# A31S13x register map
Vendor: VENDOR ABOV Semiconductor Co., Ltd.; Series: A31S13x; File version: 1.0
CPU: CM0+ r0p1, little endian, no MPU, no FPU, VTOR, 2 interrupt priority bits
Registers are 32-bit, read-write, reset 0x0 unless marked. A register's access mark holds for its fields unless they carry their own. Offsets are from the block's base; [hi:lo] are bit positions; 'fields as' and 'values as' point back to an identical list.

## TIMER2n — Timer/Counter 2n
Base 0x52000000
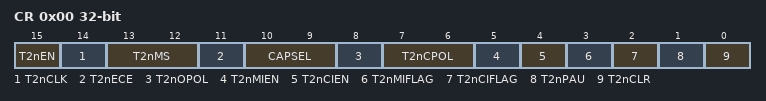
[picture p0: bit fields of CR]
0x00 CR — TIMER2n Control Register
  [15] T2nEN — TIMER2n Operation Enable
  [14] T2nCLK — TIMER2n Clock Selection
  [13:12] T2nMS — TIMER2n Operation Mode Selection
  [11] T2nECE — TIMER2n External Clock Edge Selection
  [10:9] CAPSEL — TIMER2n Capture Signal Selection
  [8] T2nOPOL — TIMER2n Output Polarity Selection
  [7:6] T2nCPOL — TIMER2n Capture Polarity Selection
  [5] T2nMIEN — TIMER2n Match Interrupt Enable
  [4] T2nCIEN — TIMER2n Capture Interrupt Enable
  [3] T2nMIFLAG — TIMER2n Match Interrupt Flag
  [2] T2nCIFLAG — TIMER2n Capture Interrupt Flag
  [1] T2nPAU — TIMER2n Counter Temporary Pause Control
  [0] T2nCLR — TIMER2n Counter and Prescaler Clear
0x04 ADR reset 0xFFFFFFFF — TIMER2n A Data Register
  [31:0] ADATA — TIMER2n A Data
0x08 BDR reset 0xFFFFFFFF — TIMER2n B Data Register
  [31:0] BDATA — TIMER2n B Data
0x0C CAPDR ro — TIMER2n Capture Data Register
  [31:0] CAPD — TIMER2n Capture Data
0x10 PREDR reset 0xFFF — TIMER2n Prescaler Data Register
  [11:0] PRED — TIMER2n Prescaler Data
0x14 CNT ro — TIMER2n Counter Register
  [31:0] CNT — TIMER2n Counter

## TIMER20 — Timer/Counter 20
Base 0x40002500
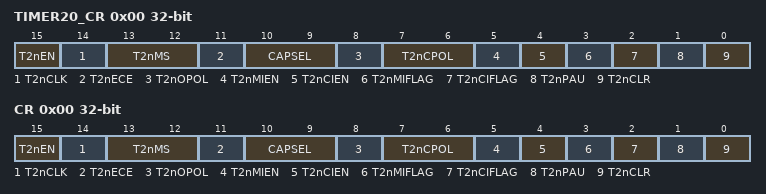
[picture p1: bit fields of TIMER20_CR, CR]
0x00 TIMER20_CR (alternate view of CR) — TIMER2n Control Register
  [15] T2nEN — TIMER2n Operation Enable
  [14] T2nCLK — TIMER2n Clock Selection
  [13:12] T2nMS — TIMER2n Operation Mode Selection
  [11] T2nECE — TIMER2n External Clock Edge Selection
  [10:9] CAPSEL — TIMER2n Capture Signal Selection
  [8] T2nOPOL — TIMER2n Output Polarity Selection
  [7:6] T2nCPOL — TIMER2n Capture Polarity Selection
  [5] T2nMIEN — TIMER2n Match Interrupt Enable
  [4] T2nCIEN — TIMER2n Capture Interrupt Enable
  [3] T2nMIFLAG — TIMER2n Match Interrupt Flag
  [2] T2nCIFLAG — TIMER2n Capture Interrupt Flag
  [1] T2nPAU — TIMER2n Counter Temporary Pause Control
  [0] T2nCLR — TIMER2n Counter and Prescaler Clear
0x00 CR — TIMER2n Control Register
  fields as TIMER20_CR
0x04 ADR reset 0xFFFFFFFF — TIMER2n A Data Register
  [31:0] ADATA — TIMER2n A Data
0x08 BDR reset 0xFFFFFFFF — TIMER2n B Data Register
  [31:0] BDATA — TIMER2n B Data
0x0C CAPDR ro — TIMER2n Capture Data Register
  [31:0] CAPD — TIMER2n Capture Data
0x10 PREDR reset 0xFFF — TIMER2n Prescaler Data Register
  [11:0] PRED — TIMER2n Prescaler Data
0x14 CNT ro — TIMER2n Counter Register
  [31:0] CNT — TIMER2n Counter

## TIMER21 — Timer/Counter 21
Base 0x40002600
Registers as TIMER20 (with TIMER20 read as TIMER21); these are added or differ:
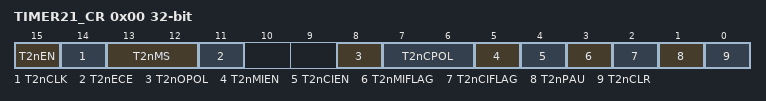
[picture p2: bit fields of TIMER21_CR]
0x00 TIMER21_CR (alternate view of CR) — TIMER2n Control Register
  [15] T2nEN — TIMER2n Operation Enable
  [14] T2nCLK — TIMER2n Clock Selection
  [13:12] T2nMS — TIMER2n Operation Mode Selection
  [11] T2nECE — TIMER2n External Clock Edge Selection
  [8] T2nOPOL — TIMER2n Output Polarity Selection
  [7:6] T2nCPOL — TIMER2n Capture Polarity Selection
  [5] T2nMIEN — TIMER2n Match Interrupt Enable
  [4] T2nCIEN — TIMER2n Capture Interrupt Enable
  [3] T2nMIFLAG — TIMER2n Match Interrupt Flag
  [2] T2nCIFLAG — TIMER2n Capture Interrupt Flag
  [1] T2nPAU — TIMER2n Counter Temporary Pause Control
  [0] T2nCLR — TIMER2n Counter and Prescaler Clear

## UARTn
Base 0x58000000
Same registers: UART0 0x40004000, UART1 0x40004100
0x00 RBR ro — UARTn Receive Data Buffer Register
  [7:0] RBR — UARTn Receive Data Buffer
0x00 THR wo — UARTn Transmit Data Hold Register
  [7:0] THR — UARTn Transmit Data Hold
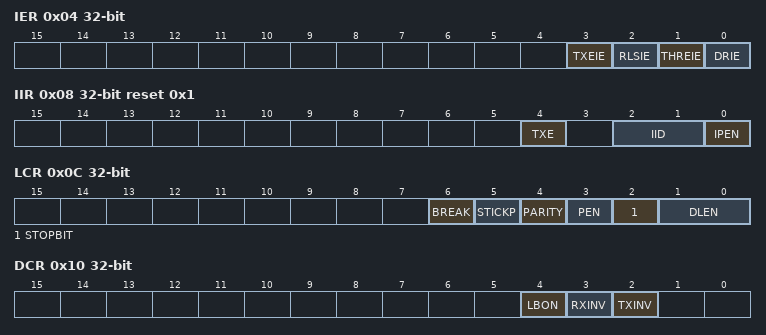
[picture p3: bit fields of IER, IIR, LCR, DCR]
0x04 IER — UARTn Interrupt Enable Register
  [3] TXEIE — Transmit Empty Interrupt Enable
  [2] RLSIE — Receiver Line Status Interrupt Enable
  [1] THREIE — Transmit Holding Register Empty Interrupt Enable
  [0] DRIE — Data Receive Interrupt Enable
0x08 IIR ro reset 0x1 — UARTn Interrupt ID Register
  [4] TXE — Transmit Complete Interrupt Source ID
  [2:1] IID — UARTn Interrupt ID
  [0] IPEN — Interrupt Pending
0x0C LCR — UARTn Line Control Register
  [6] BREAK — Transfer Break Control
  [5] STICKP — Force Parity
  [4] PARITY — Parity Mode and Parity Stuck Selection
  [3] PEN — Parity Bit Transfer Enable
  [2] STOPBIT — Stop Bit Length Selection
  [1:0] DLEN — Data Length Selection
0x10 DCR — UARTn Data Control Register
  [4] LBON — Local Loopback Test Mode Enable
  [3] RXINV — Receive Data Inversion Selection
  [2] TXINV — Transmit Data Inversion Selection
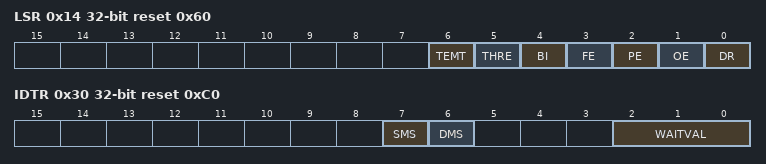
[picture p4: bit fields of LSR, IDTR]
0x14 LSR ro reset 0x60 — UARTn Line Status Register
  [6] TEMT — Transmit Empty
  [5] THRE — Transmit Holding Empty
  [4] BI — Break Condition Indication
  [3] FE — Frame Error Indicator
  [2] PE — Parity Error Indicator
  [1] OE — Overrun Error Indicator
  [0] DR — Data Receive Indicator
0x20 BDR — UARTn Baud Rate Divisor Latch Register
  [15:0] BDR — Baud Rate Divider Latch Value. Baud rate = fUARTnCLK/(16 x BDR[15:0] x 2)
0x24 BFR — UARTn Baud Rate Fractional Counter Value
  [7:0] BFR — Fraction Counter value
    0=Disable fraction counter
0x30 IDTR reset 0xC0 — UARTn Inter-frame Delay Time Register
  [7] SMS — Start Bit Multi Sampling Enable
  [6] DMS — Data Bit Multi sampling enable
  [2:0] WAITVAL — Wait Time Value
